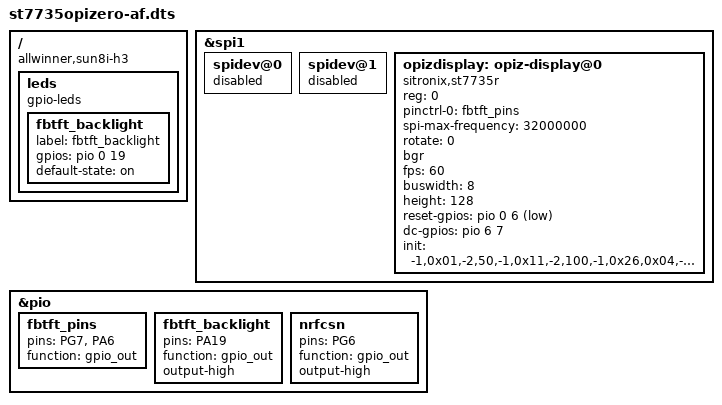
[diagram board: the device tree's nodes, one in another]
// https://github.com/nuharaf/fbtft-dt-overlay

/dts-v1/;
/plugin/;

/ {
	compatible = "allwinner,sun8i-h3";

	fragment@0 {
		target = <&spi1>;
		__overlay__ {
			status = "okay";

			spidev@0{
				status = "disabled";
			};

			spidev@1{
				status = "disabled";
			};
		};
	};

	fragment@1 {
		target = <&pio>;
		__overlay__ {
			fbtft_pins: fbtft_pins {
		                pins = "PG7", "PA6";
                		function = "gpio_out";
			};
			fbtft_backlight: fbtft_backlight {
				pins = "PA19";
				function = "gpio_out";
				output-high;
			};
			nrfcsn: nrfcsn {
				pins = "PG6";
				function = "gpio_out";
				output-high;
			};
		};
	};

	fragment@2 {
		target-path = "/";
		__overlay__ {
            leds {
                compatible = "gpio-leds";

                fbtft_backlight {
                    label = "fbtft_backlight";
                    gpios =  <&pio 0 19 0>; // port A=0 pin=19 output=0
                    default-state = "on";
                };
            };
		};
	};
	fragment@4 {
		target = <&spi1>;
		__overlay__ {
			/* needed to avoid dtc warning */
			#address-cells = <1>;
			#size-cells = <0>;

			opizdisplay: opiz-display@0{
				compatible = "sitronix,st7735r";
				reg = <0>;
				pinctrl-names = "default";
				pinctrl-0 = <&fbtft_pins>;

				spi-max-frequency = <32000000>;
				rotate = <0>;
				bgr;
				fps = <60>;
				buswidth = <8>;
				height = <128>;
				reset-gpios = <&pio 0 6 1>;
				dc-gpios = <&pio 6 7 0>;
                init = <-1,0x01,-2,50,-1,0x11,-2,100,-1,0x26,0x04,-1,0xb1,0x0b,0x14,-1,0xc0,0x08,0x00,-1,0xc1,0x05,-1,0xc5,0x41,0x30,-1,0xc7,0xc1,-1,0xEC,0x1b,-1,0x3a,0x55,-2,100,-1,0x2a,0x00,0x00,0x00,0x7f,-1,0x2b,0x00,0x00,0x00,0x9f,-1,0x36,0xc8,-1,0xb7,0x00,-1,0xf2,0x00,-1,0xe0,0x28,0x24,0x22,0x31,0x2b,0x0e,0x53,0xa5,0x42,0x16,0x18,0x12,0x1a,0x14,0x03,-2,50,-1,0xe1,0x17,0x1b,0x1d,0x0e,0x14,0x11,0x2c,0xa5,0x3d,0x09,0x27,0x2d,0x25,0x2b,0x3c,-2,50,-1,0x13,-2,10,-1,0x29,-2,500,-3>;
			};
		};
	};
};
